# bbfc_me10 register map
Registers are read-write, no defined reset value unless marked. A register's access mark holds for its fields unless they carry their own. Offsets are from the block's base; lines under a group give offsets from that group; [hi:lo] are bit positions; {n}, {i} and the like mark numbered series; 'fields as' and 'values as' point back to an identical list; <NAME> marks a mode.

## Memory map
0x40005800 BBFC size 0x400 — Battery Backed Function Control Register.

## BBFC — Battery Backed Function Control Register.
Base 0x40005800
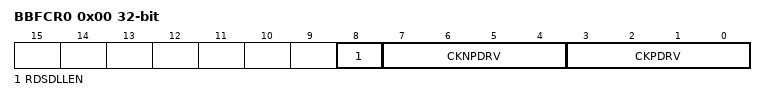
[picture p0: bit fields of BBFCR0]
0x00 BBFCR0 — Register 0.
  [8] RDSDLLEN — Hyperbus RDS DLL Enable.
    0=dis; 1=en
  [7:4] CKNPDRV — Hyperbus CKN Drive Setting.
  [3:0] CKPDRV — Hyperbus CK Drive Setting.
